# A8107M register map
Vendor: Amiccom Electronics Co., Ltd.; Series: A8107M; File version: 1.0
A8107M0 SVD File
CPU: CM0 r0p0, little endian, no MPU, no FPU, 2 interrupt priority bits
Registers are 32-bit, read-write, reset 0x0 unless marked. A register's access mark holds for its fields unless they carry their own. Offsets are from the block's base; lines under a group give offsets from that group; [hi:lo] are bit positions; {n}, {i} and the like mark numbered series; 'fields as' and 'values as' point back to an identical list; <NAME> marks a mode.

## Memory map
0x40000000 TIMER0 size 0x100 — Timer
0x40001000 TIMER1 size 0x100 — Timer
0x40002000 DUALTIMER1 size 0x20 — Dual Timer
0x40002020 DUALTIMER2 size 0x20 — Dual Timer
0x40003000 I2CM size 0x100 — I2C Master
0x40003800 I2CS size 0x100 — I2C Slave
0x40004000 UART0 size 0x100 — Timer
0x40005000 UART1 size 0x100 — Timer
0x40006000 UART2 size 0x100 — Timer
0x40008000 WATCHDOG size 0x1000
0x40010000 GPIO0 size 0x1000 — General Purpose I/O

## Interrupts
1 UART0
5 UART2
6 GPIO0
8 TIMER0
9 TIMER1
10 DUALTIMER (DUALTIMER1, DUALTIMER2)
13 UART1
17 I2C (I2CM, I2CS)

## TIMER0 — Timer
Base 0x40000000
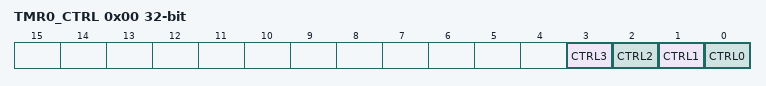
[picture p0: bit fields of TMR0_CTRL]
0x00 TMR0_CTRL — Timer 0 Control Register
  [3] CTRL3 — Timer interrupt enable
    0=Disable; 1=Enable
  [2] CTRL2 — Select external input as clock
    0=Disable; 1=Enable (Timer decrement when EXTIN rising edge)
  [1] CTRL1 — Select external input as enable
    0=Disable; 1=Enable (Timer stop when EXTIN=0)
  [0] CTRL0 — Enable decrement control
    0=Disable (Timer stop decrement); 1=Enable (Timer start decrement)
0x04 TMR0_VALUE — Timer 0 Current Value Register
0x08 TMR0_RELOAD — Timer 0 Reload Register
0x0C TMR0_INT — Timer 0 Interrupt Status Register
  [0] INTSTATUS — interrupt status (TIMERINT status)
    0=Interrupt not occur; 1=Interrupt occur, write 1 to clear INTSTATUS

## TIMER1 — Timer
Base 0x40001000
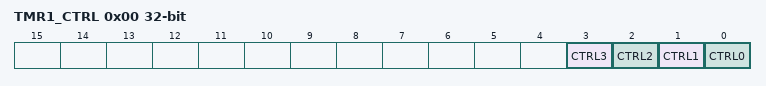
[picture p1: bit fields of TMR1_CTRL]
0x00 TMR1_CTRL — Timer 1 Control Register
  [3] CTRL3 — Timer interrupt enable
    0=Disable; 1=Enable
  [2] CTRL2 — Select external input as clock
    0=Disable; 1=Enable (Timer decrement when EXTIN rising edge)
  [1] CTRL1 — Select external input as enable
    0=Disable; 1=Enable (Timer stop when EXTIN=0)
  [0] CTRL0 — Enable decrement control
    0=Disable (Timer stop decrement); 1=Enable (Timer start decrement)
0x04 TMR1_VALUE — Timer 1 Current Value Register
0x08 TMR1_RELOAD — Timer 1 Reload Register
0x0C TMR1_INT — Timer 1 Interrupt Status Register
  [0] INTSTATUS — interrupt status (TIMERINT status)
    0=Interrupt not occur; 1=Interrupt occur, write 1 to clear INTSTATUS

## DUALTIMER1 — Dual Timer
Base 0x40002000
0x00 DUALTMR1_LOAD — Dual Timer 1 Load register
0x04 DUALTMR1_VALUE — Dual Timer 1 current Value register
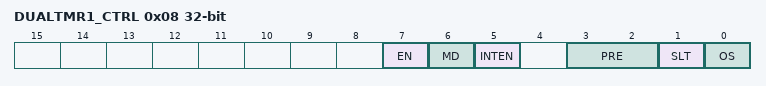
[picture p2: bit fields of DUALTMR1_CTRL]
0x08 DUALTMR1_CTRL (reset mask 0xF) — Dual Timer 1 Control register
  [7] EN — Dual timer x Enable
    0=Disable; 1=Enable (Dual timer start count down)
  [6] MD — Dual timer Mode
    0=Free-running mode; 1=Periodic mode
  [5] INTEN — Dual timer interrupt enable
    0=Dual Timer interrupt disable; 1=Dual Timer interrupt enable
  [3:2] PRE — Dual timer size selects 16-bit or 32-bit counter operation
    0=Dual timer prescale (Clock is divided by 1); 1=Dual timer prescale (Clock is divided by 16); 2=Dual timer prescale (Clock is divided by 256); 3=Dual timer prescale (Undefined)
  [1] SLT — Dual timer size selects 16-bit or 32-bit counter operation
    0=16-bit counter; 1=32-bit counter
  [0] OS — Dual timer one-shot count selects
    0=Wrapping; 1=One-shot
0x0C DUALTMR1_INTCLR wo — Dual Timer 1 Interrupt Clear register
  [0] INTCLR — Timer interrupt clear. Write any value to this register to clean RIS and MIS.
    0=Timer interrupt clear; 1=Timer interrupt clear
0x10 DUALTMR1_RIS ro — Dual Timer 1 Raw Interrupt register
  [0] RIS — Dual timer Raw interrupt status
    0=VALUE[31:0] not counts down to 0; 1=VALUE[31:0] had counted down to 0
0x14 DUALTMR1_MIS ro — Dual Timer 1 Mask Interrupt register
  [0] MIS — Dual timer interrupt enabled status from the counter
    0=INTEN=0 or RIS=0. Dual Timer interrupt not occur; 1=INTEN=1 and RIS=1. Dual Timer interrupt occur
0x18 DUALTMR1_BGLOAD — Dual Timer 1 Back Ground Load register

## Notices in the file
Copyright (C) 2012-2014 ARM Limited. All rights reserved.
Purpose: System Viewer Description (SVD) Example (Schema Version 1.1)
This is a description of a none-existent and incomplete device
for demonstration purposes only.
Redistribution and use in source and binary forms, with or without
modification, are permitted provided that the following conditions are met:
- Redistributions of source code must retain the above copyright
notice, this list of conditions and the following disclaimer.
- Redistributions in binary form must reproduce the above copyright
notice, this list of conditions and the following disclaimer in the
documentation and/or other materials provided with the distribution.
- Neither the name of ARM nor the names of its contributors may be used
to endorse or promote products derived from this software without
specific prior written permission.
THIS SOFTWARE IS PROVIDED BY THE COPYRIGHT HOLDERS AND CONTRIBUTORS "AS IS"
AND ANY EXPRESS OR IMPLIED WARRANTIES, INCLUDING, BUT NOT LIMITED TO, THE
IMPLIED WARRANTIES OF MERCHANTABILITY AND FITNESS FOR A PARTICULAR PURPOSE
ARE DISCLAIMED. IN NO EVENT SHALL COPYRIGHT HOLDERS AND CONTRIBUTORS BE
LIABLE FOR ANY DIRECT, INDIRECT, INCIDENTAL, SPECIAL, EXEMPLARY, OR
CONSEQUENTIAL DAMAGES (INCLUDING, BUT NOT LIMITED TO, PROCUREMENT OF
SUBSTITUTE GOODS OR SERVICES; LOSS OF USE, DATA, OR PROFITS; OR BUSINESS
INTERRUPTION) HOWEVER CAUSED AND ON ANY THEORY OF LIABILITY, WHETHER IN
CONTRACT, STRICT LIABILITY, OR TORT (INCLUDING NEGLIGENCE OR OTHERWISE)
ARISING IN ANY WAY OUT OF THE USE OF THIS SOFTWARE, EVEN IF ADVISED OF THE
POSSIBILITY OF SUCH DAMAGE.
